# M55M1 register map
File version: 1.0
Registers are 32-bit, read-write, reset 0x0 unless marked. A register's access mark holds for its fields unless they carry their own. Offsets are from the block's base; [hi:lo] are bit positions; {n}, {i} and the like mark numbered series; 'fields as' and 'values as' point back to an identical list.

## KPI_NS — KPI Register Map
Base 0x50294000
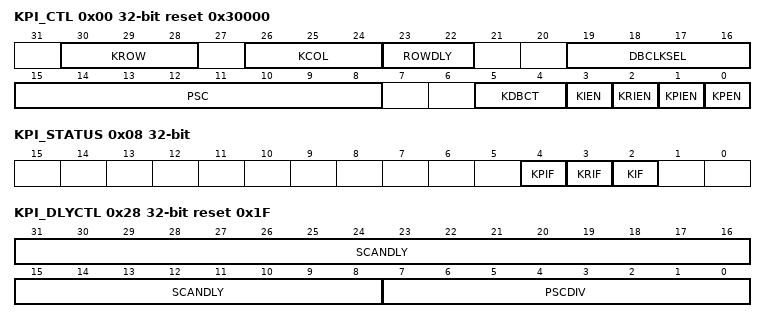
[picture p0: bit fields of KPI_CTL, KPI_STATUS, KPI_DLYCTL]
0x00 KPI_CTL reset 0x30000 — Keypad Control Register
  [30:28] KROW — Keypad Matrix ROW Number. The keypad matrix is set by ROW x COL. The ROW number can be set 2 to 6.
    {v}={v+1} (v=1..5)
  [26:24] KCOL — Keypad Matrix COL Number. The keypad matrix is set by ROW x COL. The COL number can be set 1 to 8.
    {v}={v+1} (v=0..7)
  [23:22] ROWDLY — Scan Row Delay. Setting delay cycle when row change, for avoid KPI from detecting wrong key.
    0=4 XCLOCK; 1=8 XCLOCK; 2=16 XCLOCK; 3=32 XCLOCK
  [19:16] DBCLKSEL — Scan in De-bounce Sampling Cycle Selection
    3=Sample interrupt input once per 8 XCLOCK; 4=Sample interrupt input once per 16 XCLOCK; 5=Sample interrupt input once per 32 XCLOCK; 6=Sample interrupt input once per 64 XCLOCK; 7=Sample interrupt input once per 128 XCLOCK; 8=Sample interrupt input once per 256 XCLOCK; 9=Sample interrupt input once per 512 XCLOCK; 10=Sample interrupt input once per 1024 XCLOCK; 11=Sample interrupt input once per 2048 XCLOCK; 12=Sample interrupt input once per 4096 XCLOCK; 13=Sample interrupt input once per 8192 XCLOCK
  [15:8] PSC — Row Scan Cycle Pre-scale Value. This value is used to pre-scale row scan cycle. The pre-scale counter is clocked by the divided crystal clock, XCLOCK. The divided number is from 1 to 256. For example, if the crystal clock is 1 MHz then the XCLOCK period is 1us. If the keypad matric is 3x3 then
  [5:4] KDBCT — Keypad De-bounce Cycle Time. For keypad debounce, keypad will generate an interrupt when key press or key release continued n * key array scan time. Note: It would need more time to indicate key press and release event when users selected more debounce cycle time.
    {v}=n={v+1} (v=0..3)
  [3] KIEN — Key Interrupt Enable Bit
    0=Keypad interrupt Disabled; 1=Keypad interrupt Enabled
  [2] KRIEN — Key Release Interrupt Enable Bit. The keypad controller will generate an interrupt when the controller detects keypad status changes from press to release.
    0=Keypad release interrupt Disabled; 1=Keypad release interrupt Enabled
  [1] KPIEN — Key Press Interrupt Enable Bit. The keypad controller will generate an interrupt when the controller detects any effective key press.
    0=Keypad press interrupt Disabled; 1=Keypad press interrupt Enabled
  [0] KPEN — Keypad Enable Bit. Setting this bit high enables the key scan function.
    0=Keypad scan Disabled; 1=Keypad scan Enabled
0x08 KPI_STATUS ro — Keypad Status Register
  [4] KPIF — Key Press Interrupt Flag. This bit indicates that some keys (one or multiple key) have been pressed. When READ: Note: To clear KPIF, software must clear each pressing flag that are shown on KPI_KPF0/1 registers.
    0=No key press; 1=At least one key press
  [3] KRIF — Key Release Interrupt Flag. This bit indicates that some keys (one or multiple key) have been released. When READ: Note: To clear KRIF, software must clear each releasing flag that are shown on KPI_KRF0/1 registers.
    0=No key release; 1=At least one key release
  [2] KIF — Key Interrupt Flag. This bit indicates the key scan interrupt is active when any key press or key release. When READ: Note: To clear KIF, software must clear KPIF and KRIF.
    0=No reset; 1=Key press/Key release interrupt occurred
0x10 KPI_KST0 ro reset 0xFFFFFFFF — Keypad State Register 0
  [31:0] KSTmn — Key State m is row number, n is column number.
    0=Key is pressing; 1=Key is releasing
0x14 KPI_KST1 ro reset 0xFFFF — Keypad State Register 1
  [15:0] KSTmn — Key State m is row number, n is column number.
    0=Key is pressing; 1=Key is releasing
0x18 KPI_KPF0 — Lower 32 Key Press Flag Register 0
  [31:0] KPFmn — Lower 32 Key Press Flag m is row number, n is column number. Note: This bit will be set by hardware, and should be cleared by software writing 1.
    0=No key event; 1=Corresponding key has a high to low event change
0x1C KPI_KPF1 — Upper 32 Key Press Flag Register 1
  [15:0] KPFmn — Upper 32 Key Press Flag m is row number, n is column number. Note: This bit will be set by hardware, and should be cleared by software writing 1.
    values as KPI_KPF0.KPFmn
0x20 KPI_KRF0 — Lower 32 Key Release Flag Register 0
  [31:0] KRFmn — Lower 32 Key Release Flag m is row number, n is column number. Note: This bit will be set by hardware, and should be cleared by software writing 1.
    0=No key event; 1=Corresponding key has a low to high event change
0x24 KPI_KRF1 — Upper 32 Key Release Flag Register 1
  [15:0] KRFmn — Upper 32 Key Release Flag m is row number, n is column number. Note: This bit will be set by hardware, and should be cleared by software writing 1.
    values as KPI_KRF0.KRFmn
0x28 KPI_DLYCTL reset 0x1F — Delay Control Register
  [31:8] SCANDLY — Key Array Scan Delay. This value is used to insert delay cycle between each key array scan. The key array scan delay counter is clocked by the divided crystal clock, XCLOCK. Note: If the key array scan delay is set to 0, there is no delay between each key array scan. There is no delay 1 cycle situation.
    0=No delay
  [7:0] PSCDIV — Pre-scale Divider. This value is used to divide PRESCALE that is set in KPI_CTL[15:8]. The prescale divider counter is clocked by the divided crystal clock, XCLOCK. The number is from 1 to 256.
